# MCRC_MSS_MCRC_35000000h register map
Vendor: Texas Instruments
Peripheral module from a debugger description file (folder AM261x).
Registers are 32-bit, access per field, reset 0x0 unless marked. A register's access mark holds for its fields unless they carry their own. Offsets are as the file gives them; lines under a group give offsets from that group; [hi:lo] are bit positions; {n}, {i} and the like mark numbered series; 'fields as' and 'values as' point back to an identical list; <NAME> marks a mode.

## MSS_MCRC
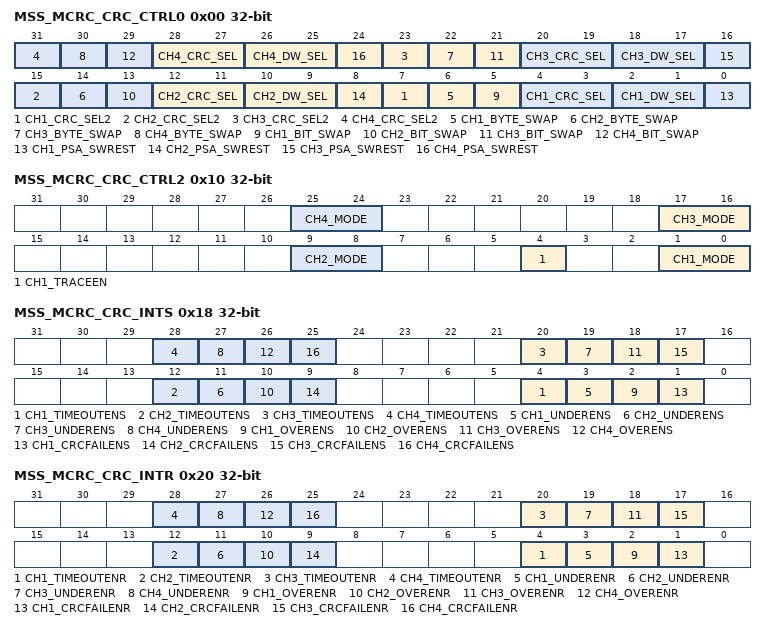
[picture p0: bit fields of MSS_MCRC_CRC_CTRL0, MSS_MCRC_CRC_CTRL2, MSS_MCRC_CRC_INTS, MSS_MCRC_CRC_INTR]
0x00 MSS_MCRC_CRC_CTRL0 rw — Contains sw reset control bit to reset PSA.
  [8n-1] CH{n}_CRC_SEL2 (n=1..4) — Refer 'CH{n}_DW_SEL' field description
  [8n-2] CH{n}_BYTE_SWAP (n=1..4) — BYTE SWAP Enable across Data Size0 Byte Swap Disabled1 Byte Swap enabled.
  [8n-3] CH{n}_BIT_SWAP (n=1..4) — msb/lsb SWAPPING 0 msb [most significant bit First]1 lsb [least significant bit First]
  [28:27] CH4_CRC_SEL — CRC type select. {CH1_CRC_SEL2,CH1_CRC_SEL[1:0]}000 CRC-64001 - CRC-16010 CRC-32100 - VDA CAN, SAE-J1850 CRC-8101 - H2F, Autosar 4.0110 - CASTAGNOLI, iSCSI111 / 011 - E2E Profile 4
  [8n-6:8n-7] CH{n}_DW_SEL (n=1..4) — CRC Data Size select.000 64 bit Data Size001 - 16 bit Data Size010 32 Bit Data Size
  [8n-8] CH{n}_PSA_SWREST (n=1..4) — Channel {n} PSA Software Reset. When set, the PSA SignatureRegister is reset to all zero. Software reset does not reset softwarereset bit itself. Therefore, CPU is required to clear this bit by Writinga 0.0 = PSA Signature Register not reset1 = PSA Signature Register reset
  [20:19] CH3_CRC_SEL — CRC type select. {CH1_CRC_SEL2,CH1_CRC_SEL[1:0]}000 CRC-64001 - CRC-16010 CRC-32100 - VDA CAN, SAE-J1850 CRC-8101 - H2F, Autosar 4.0110 - CASTAGNOLI, iSCSI111 / 011 - E2E Profile 4
  [12:11] CH2_CRC_SEL — CRC type select. {CH1_CRC_SEL2,CH1_CRC_SEL[1:0]}000 CRC-64001 - CRC-16010 CRC-32100 - VDA CAN, SAE-J1850 CRC-8101 - H2F, Autosar 4.0110 - CASTAGNOLI, iSCSI111 / 011 - E2E Profile 4
  [4:3] CH1_CRC_SEL — CRC type select. {CH1_CRC_SEL2,CH1_CRC_SEL[1:0]}000 CRC-64001 - CRC-16010 CRC-32100 - VDA CAN, SAE-J1850 CRC-8101 - H2F, Autosar 4.0110 - CASTAGNOLI, iSCSI111 / 011 - E2E Profile 4
0x08 MSS_MCRC_CRC_CTRL1 — Contains power down control bit.
  [0] PWDN rw — Power Down. When set, MCRC moduleMCRC Module is put inpower down mode.0 = MCRC is not in power down mode1 = MCRC is in power down mode
0x10 MSS_MCRC_CRC_CTRL2 — Contains channel mode, data trace enable control bits.
  [8n-7:8n-8] CH{n}_MODE rw (n=1..4) — Channel {n} Mode:0 0 = Data Capture mode. In this mode, the PSA Signature Registerdoes not compress data when it is written. Any datawritten to PSA Signature Register is simply captured byPSA Signature Register without any compression. Thismode can be used to plant seed value into the PSA register0 1 = AUTO mode1 0 = reserved1 1 = Full-CPU mode
  [4] CH1_TRACEEN rw — Channel 1 Data Trace Enable. When set, the channel is put intodata trace mode. The channel snoops on the CPU VBUSM,ITCM, DTCM buses for any read transaction. Any read data onthese buses is compressed by the PSA Signature Register. Whensuspend is on, the PSA Signature Register does not compress anyread data on these buses.0 = Data Trace disable1 = Data Trace enable
0x18 MSS_MCRC_CRC_INTS — CRC interrupt enable register. Write one to a bit to enable a interrupt.
  [8n-4] CH{n}_TIMEOUTENS rw (n=1..4) — Channel {n} Timeout Interrupt Enable Bit. Writing a one to thisbit enable the timeout interrupt. Writing a zero has no effect.Reading from this bit gives the status [interrupt enable/disable].User and privileged mode read:0 = Timeout Interrupt disable1 = Timeout Interrupt enableUser and privileged mode write:0 = Has no effect1 = Timeout Interrupt enable
  [8n-5] CH{n}_UNDERENS rw (n=1..4) — Channel {n} Underrun Interrupt Enable Bit. Writing a one tothis bit enable the underrun interrupt. Writing a zero has no effect.Reading from this bit gives the status [interrupt enable/disable].User and privileged mode read:0 = Underrun Interrupt disable1 = Underrun Interrupt enableUser and privileged mode write:0 = Has no effect1 = Underrun Interrupt enable
  [8n-6] CH{n}_OVERENS rw (n=1..4) — Channel {n} Overrun Interrupt Enable Bit. Writing a one to thisbit enable the overrun interrupt. Writing a zero has no effect.Reading from this bit gives the status [interrupt enable/disable].User and privileged mode read:0 = Overrun Interrupt disable1 = Overrun Interrupt enableUser and privileged mode write:0 = Has no effect1 = Overrun Interrupt enable
  [8n-7] CH{n}_CRCFAILENS rw (n=1..4) — Channel {n} CRC Fail Interrupt Enable Bit. Writing a one to thisbit enable the CRC fail interrupt. Writing a zero has no effect.Reading from this bit gives the status [interrupt enable/disable].User and privileged mode read:0 = CRC Fail Interrupt disable1 = CRC Fail Interrupt enableUser and privileged mode write:0 = Has no effect1 = CRC Fail Interrupt enable
0x20 MSS_MCRC_CRC_INTR — CRC interrupt disable register. Write one to a bit to disable a interrupt.
  [8n-4] CH{n}_TIMEOUTENR rw (n=1..4) — Channel {n} Timeout Interrupt Disable Bit. Writing a one to thisbit disable the timeout interrupt. Writing a zero has no effect.Reading from this bit gives the status [interrupt enable/disable].User and privileged mode read:0 = Timeout Interrupt disable1 = Timeout Interrupt enableUser and privileged mode write:0 = Has no effect1 = Timeout Interrupt disable
  [8n-5] CH{n}_UNDERENR rw (n=1..4) — Channel {n} Underrun Interrupt Disable Bit. Writing a one tothis bit disable the underrun interrupt. Writing a zero has noeffect. Reading from this bit gives the status [interrupt enable/dis-able].User and privileged mode read:0 = Underrun Interrupt disable1 = Underrun Interrupt enableUser and privileged mode write:0 = Has no effect1 = Underrun Interrupt disable
  [8n-6] CH{n}_OVERENR rw (n=1..4) — Channel {n} Overrun Interrupt Disable Bit. Writing a one to thisbit disable the overrun interrupt. Writing a zero has no effect.Reading from this bit gives the status [interrupt enable/disable].User and privileged mode read:0 = Overrun Interrupt disable1 = Overrun Interrupt enableUser and privileged mode write:0 = Has no effect1 = Overrun Interrupt disable
  [8n-7] CH{n}_CRCFAILENR rw (n=1..4) — Channel {n} CRC Fail Interrupt Disable Bit. Writing a one to thisbit disable the CRC fail interrupt. Writing a zero has no effect.Reading from this bit gives the status [interrupt enable/disable].User and privileged mode read:0 = CRC Fail Interrupt disable1 = CRC Fail Interrupt enableUser and privileged mode write:0 = Has no effect1 = CRC Fail Interrupt disable
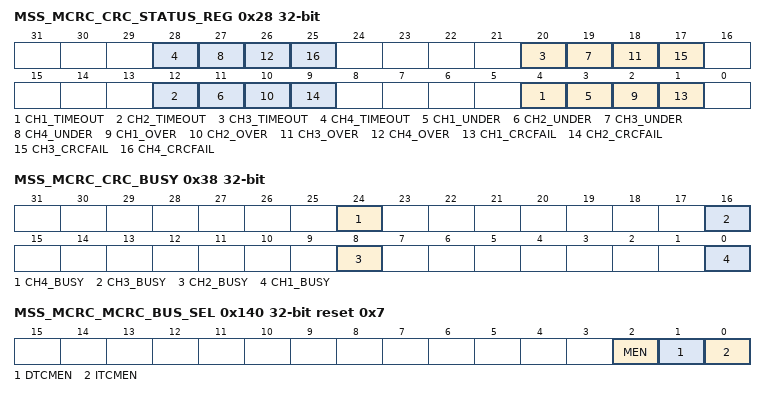
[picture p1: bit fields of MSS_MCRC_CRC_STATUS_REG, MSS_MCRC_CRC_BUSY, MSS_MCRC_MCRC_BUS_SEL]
0x28 MSS_MCRC_CRC_STATUS_REG — CRC interrupt status register. Contains interrupt flags for different types of interrupt.
  [8n-4] CH{n}_TIMEOUT rw (n=1..4) — Channel {n} CRC Timeout Status Flag. This bit is cleared byWriting a 1 to it only. Writing 0 has no effect. This bit is set inAUTO mode.0 = No timeout interrupt is active1 = Timeout interrupt is active
  [8n-5] CH{n}_UNDER rw (n=1..4) — Channel {n} CRC Underrun Status Flag. This bit is cleared byWriting a 1 to it only. Writing 0 has no effect. This bit is set inAUTO mode only0 = No underrun interrupt is active1 = Underrun interrupt is active
  [8n-6] CH{n}_OVER rw (n=1..4) — Channel {n} CRC Overrun Status Flag. This bit is cleared byWriting a 1 to it only. Writing 0 has no effect. This bit is set inAUTO mode0 = No overrun interrupt is active1 = Overrun interrupt is active
  [8n-7] CH{n}_CRCFAIL rw (n=1..4) — Channel {n} CRC Compare Fail Status Flag. This bit is clearedby Writing a 1 to it only. Writing 0 has no effect. This bit is setin AUTO mode only.0 = No CRC compare fail interrupt is active1 = CRC compare fail interrupt is active
0x30 MSS_MCRC_CRC_INT_OFFSET_REG — Register indicates highest priority pending interrupt vector address.
  [7:0] OFSTREG rw — CRC Interrupt Offset. This register indicates the highest prioritypending interrupt vector address. Reading the offset register auto-matically clear the respective interrupt flag.
0x38 MSS_MCRC_CRC_BUSY ro — Register indicates CRC busy flag for each channel.
  [24] CH4_BUSY — Ch4_BUSY. During AUTO mode, the busy flag is set when thefirst data pattern of the block is compressed and remains set untilthe the last data pattern of the block is compressed. The flag iscleared when the last data pattern of the block is compressed.
  [16] CH3_BUSY — Ch3_BUSY. During AUTO mode, the busy flag is set when thefirst data pattern of the block is compressed and remains set untilthe the last data pattern of the block is compressed. The flag iscleared when the last data pattern of the block is compressed.
  [8] CH2_BUSY — Ch2_BUSY. During AUTO mode, the busy flag is set when thefirst data pattern of the block is compressed and remains set untilthe the last data pattern of the block is compressed. The flag iscleared when the last data pattern of the block is compressed.
  [0] CH1_BUSY — CH1_BUSY. During AUTO mode, the busy flag is set when thefirst data pattern of the block is compressed and remains set untilthe the last data pattern of the block is compressed. The flag iscleared when the last data pattern of the block is compressed.
{0x0+0x40*i} MSS_MCRC_CRC_PCOUNT_REG{i} (i=1..4) — Channel {i} preload register for the pattern count.
  [19:0] CRC_PAT_COUNT{i} rw — Channel {i} Pattern Counter Preload Register. This register con-tains the number of data patterns in one sector to be compressedbefore a CRC is performed.
{0x4+0x40*i} MSS_MCRC_CRC_SCOUNT_REG{i} (i=1..4) — Channel {i} preload register for the sector count.
  [15:0] CRC_SEC_COUNT{i} rw — Channel {i} Sector Counter Preload Register. This register con-tains the number of sectors in one block of memory.
0x48 MSS_MCRC_CRC_CURSEC_REG1 — Channel 1 current sector register contains the sector number which causes CRC failure.
  [15:0] CRC_CURSEC1 rw — Channel 1 Current Sector ID Register. In AUTO mode, thisregister contains the current sector number of which the signatureverification fails. The sector counter is a free running up counter.When a sector fails, the erroneous sector number is logged intocurrent sector ID register and the CRC fail interrupt is generatedThe sector ID register is frozen until it is read and the CRC failstatus bit is cleared by CPU. While it is frozen, it does not captureanother erroneous sector number. When this condition happens,an overrun interrupt is generated instead. Once the register is readand the CRC fail interrupt flag is cleared it can capture new erro-neous sector number.
{0xC+0x40*i} MSS_MCRC_CRC_WDTOPLD{i} (i=1..4) — Channel {i} timeout pre-load value to check if within a given time DMA initiates a block transfer.
  [23:0] CRC_WDTOPLD{i} rw — Channel {i} Watchdog Timeout Counter Preload Register. Thisregister contains the number of clock cycles within which theDMA must transfer the next block of data patterns.
{0x10+0x40*i} MSS_MCRC_CRC_BCTOPLD{i} (i=1..4) — Channel {i} timeout pre-load value to check if one block of patterns are compressed with a given time.
  [23:0] CRC_BCTOPLD{i} rw — Channel {i} Block Complete Timeout Counter Preload Regis-ter. This register contains the number of clock cycles withinwhich the CRC for an entire block needs to complete before atimeout interrupt is generated.
0x60 MSS_MCRC_PSA_SIGREGL1 rw — Channel 1 PSA signature low register.
  [31:0] PSASIG1_31_0 — Channel 1 PSA Signature Low Register. This register containsthe value stored at PSASIG1[31:0] register.
0x64 MSS_MCRC_PSA_SIGREGH1 rw — Channel 1 PSA signature high register.
  [31:0] PSA_SIG1_63_32 — Channel 1 PSA Signature High Register. This register containsthe value stored at PSASIG1[63:32] register.
0x68 MSS_MCRC_CRC_REGL1 rw — Channel 1 CRC value low register.
  [31:0] CRC1_31_0 — Channel 1 CRC Value Low Register. This register contains thecurrent known good signature value stored at CRC1[31:0] regis-ter.
0x6C MSS_MCRC_CRC_REGH1 rw — Channel 1 CRC value high register.
  [31:0] CRC1_63_32 — Channel 1 CRC Value High Register. This register contains thecurrent known good signature value stored at CRC1[63:32] regis-ter.
0x70 MSS_MCRC_PSA_SECSIGREGL1 ro — Channel 1 PSA sector signature low regis-ter.
  [31:0] PSASECSIG1_31_0 — Channel 1 PSA Sector Signature Low Register. This registercontains the value stored at PSASECSIG1[31:0] register.
0x74 MSS_MCRC_PSA_SECSIGREGH1 ro — Channel 1 PSA sector signature high regis-ter.
  [31:0] PSASECSIG1_63_32 — Channel 1 PSA Sector Signature High Register. This registercontains the value stored at PSASECSIG1[63:32] register.
{0x38+0x40*i} MSS_MCRC_RAW_DATAREGL{i} ro (i=1..4) — Channel {i} un-compressed raw data low register.
  [31:0] RAW_DATA{i}_31_0 — Channel {i} Raw Data Low Register. This register contains bit31:0 of the un-compressed raw data.
0x7C MSS_MCRC_RAW_DATAREGH1 ro — Channel 1 un-compressed raw data high register.
  [31:0] RAW_DATA1_63_32 — Channel 1 Raw Data High Register. This register contains bit63:32 of the un-compressed raw data.
{0x8+0x40*i} MSS_MCRC_CRC_CURSEC_REG{i} (i=2..4) — Channel {i} current sector register contains the sector number which causes CRC fail-ure.
  [15:0] CRC_CURSEC{i} rw — Channel {i} Current Sector ID Register. In AUTO mode, thisregister contains the current sector number of which the signatureverification fails. The sector counter is a free running up counter.When a sector fails, the erroneous sector number is logged intocurrent sector ID register and the CRC fail interrupt is generatedThe sector ID register is frozen until it is read and the CRC failstatus bit is cleared by CPU. While it is frozen, it does not captureanother erroneous sector number. When this condition happens,an overrun interrupt is generated instead. Once the register is readand the CRC fail interrupt flag is cleared it can capture new erro-neous sector number.
{0x20+0x40*i} MSS_MCRC_PSA_SIGREGL{i} rw (i=2..4) — Channel {i} PSA signature low register.
  [31:0] PSASIG{i}_31_0 — Channel {i} PSA Signature Low Register. This register containsthe value stored at PSASIG2[31:0] register.
{0x24+0x40*i} MSS_MCRC_PSA_SIGREGH{i} rw (i=2..4) — Channel {i} PSA signature high register.
  [31:0] PSA_SIG{i}_63_32 — Channel {i} PSA Signature High Register. This register containsthe value stored at PSASIG2[63:32] register.
{0x28+0x40*i} MSS_MCRC_CRC_REGL{i} rw (i=2..4) — Channel {i} CRC value low register.
  [31:0] CRC{i}_31_0 — Channel {i} CRC Value Low Register. This register contains thecurrent known good signature value stored at CRC2[31:0] regis-ter.
{0x2C+0x40*i} MSS_MCRC_CRC_REGH{i} rw (i=2..4) — Channel {i} CRC value high register.
  [31:0] CRC{i}_63_32 — Channel {i} CRC Value High Register. This register contains thecurrent known good signature value stored at CRC2[63:32] regis-ter.
{0x30+0x40*i} MSS_MCRC_PSA_SECSIGREGL{i} ro (i=2..4) — Channel {i} PSA sector signature low regis-ter.
  [31:0] PSASECSIG{i}_31_0 — Channel {i} PSA Sector Signature Low Register. This registercontains the value stored at PSASECSIG2[31:0] register.
{0x34+0x40*i} MSS_MCRC_PSA_SECSIGREGH{i} ro (i=2..4) — Channel {i} PSA sector signature high regis-ter.
  [31:0] PSASECSIG{i}_63_32 — Channel {i} PSA Sector Signature High Register. This registercontains the value stored at PSASECSIG2[63:32] register.
{0x3C+0x40*i} MSS_MCRC_RAW_DATAREGH{i} ro (i=2..4) — Channel {i} un-compressed raw data high Register.
  [31:0] RAW_DATA{i}_63_32 — Channel {i} Raw Data High Register. This register contains bit63:32 of the un-compressed raw data.
0x140 MSS_MCRC_MCRC_BUS_SEL rw reset 0x7 — Disables either or all tracing of data buses.
  [2] MEN — MEn. Enable/disables the tracing of VBUSM0:Tracing of VBUSM master bus has been disabled1:Tracing of VBUSM master bus has been enabled
  [1] DTCMEN — DTCMEn. Enable/disables the tracing of data TCM0:Tracing of DTCM_ODD and DTCM_EVEN buses have been disabled1:Tracing of DTCM_ODD and DTCM_EVEN buses have been enabled
  [0] ITCMEN — ITCMEn. Enable/disables the tracing of instruction TCM0:Tracing of ITCM bus has been disabled1:Tracing of ITCM bus has been enabled
